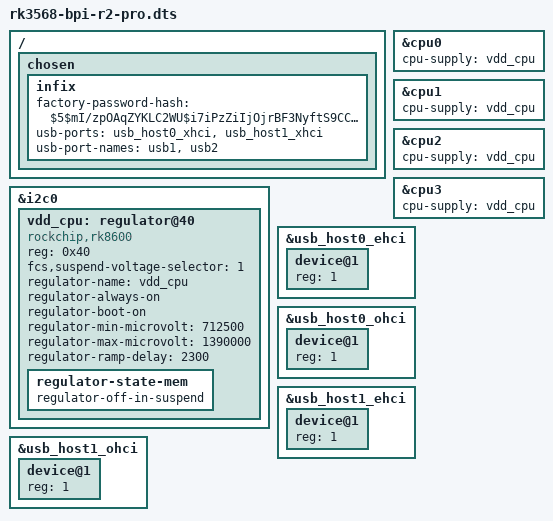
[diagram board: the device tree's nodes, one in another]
#include <arm64/rockchip/rk3568-bpi-r2-pro.dts>

/ {
	chosen {
		infix {
			/* Default admin user password: 'admin' */
			factory-password-hash = "$5$mI/zpOAqZYKLC2WU$i7iPzZiIjOjrBF3NyftS9CCq8dfYwHwrmUK097Jca9A";
			usb-ports = <&usb_host0_xhci>, <&usb_host1_xhci>;
			usb-port-names = "usb1", "usb2";
		};
	};
};

&cpu0 {
	cpu-supply = <&vdd_cpu>;
};

&cpu1 {
	cpu-supply = <&vdd_cpu>;
};

&cpu2 {
	cpu-supply = <&vdd_cpu>;
};

&cpu3 {
	cpu-supply = <&vdd_cpu>;
};

&i2c0 {
	vdd_cpu: regulator@40 {
		compatible = "rockchip,rk8600";
		reg = <0x40>;
		fcs,suspend-voltage-selector = <1>;
		regulator-name = "vdd_cpu";
		regulator-always-on;
		regulator-boot-on;
		regulator-min-microvolt = <712500>;
		regulator-max-microvolt = <1390000>;
		regulator-ramp-delay = <2300>;

		regulator-state-mem {
			regulator-off-in-suspend;
		};
	};
};

/* USB lines of the Mini PCIe (CN11) and M.2 Key-E (CN13) slots */
&usb_host0_ehci {
	#address-cells = <1>;
	#size-cells = <0>;

	device@1 {
		reg = <1>;
	};
};

&usb_host0_ohci {
	#address-cells = <1>;
	#size-cells = <0>;

	device@1 {
		reg = <1>;
	};
};

&usb_host1_ehci {
	#address-cells = <1>;
	#size-cells = <0>;

	device@1 {
		reg = <1>;
	};
};

&usb_host1_ohci {
	#address-cells = <1>;
	#size-cells = <0>;

	device@1 {
		reg = <1>;
	};
};
